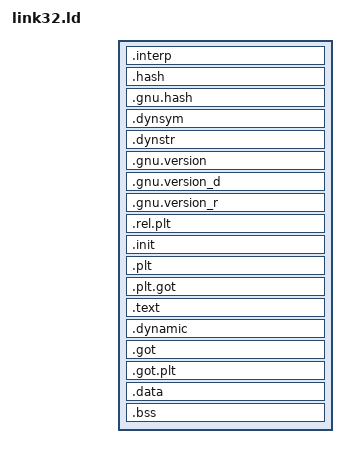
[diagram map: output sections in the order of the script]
/* Script for -z combreloc: combine and sort reloc sections */
/* Copyright (C) 2014-2015 Free Software Foundation, Inc.
   Copying and distribution of this script, with or without modification,
   are permitted in any medium without royalty provided the copyright
   notice and this notice are preserved.  */
OUTPUT_FORMAT("elf32-i386", "elf32-i386",
	      "elf32-i386")
OUTPUT_ARCH(i386)
ENTRY(_start)
SEARCH_DIR("=/usr/local/lib/i386-linux-gnu"); SEARCH_DIR("=/lib/i386-linux-gnu"); SEARCH_DIR("=/usr/lib/i386-linux-gnu"); SEARCH_DIR("=/usr/local/lib32"); SEARCH_DIR("=/lib32"); SEARCH_DIR("=/usr/lib32"); SEARCH_DIR("=/usr/local/lib"); SEARCH_DIR("=/lib"); SEARCH_DIR("=/usr/lib"); SEARCH_DIR("=/usr/i386-linux-gnu/lib32"); SEARCH_DIR("=/usr/x86_64-linux-gnu/lib32"); SEARCH_DIR("=/usr/i386-linux-gnu/lib");
SECTIONS
{
  /* Read-only sections, merged into text segment: */
  . = SEGMENT_START("text-segment", 0x08048000) + SIZEOF_HEADERS;
  .interp         : { *(.interp) }
  .hash           : { *(.hash) }
  .gnu.hash       : { *(.gnu.hash) }
  .dynsym         : { *(.dynsym) }
  .dynstr         : { *(.dynstr) }
  .gnu.version    : { *(.gnu.version) }
  .gnu.version_d  : { *(.gnu.version_d) }
  .gnu.version_r  : { *(.gnu.version_r) }
  .rel.plt        :
    {
      *(.rel.plt)
      PROVIDE_HIDDEN (__rel_iplt_start = .);
      *(.rel.iplt)
      PROVIDE_HIDDEN (__rel_iplt_end = .);
    }
  .init           :
  {
    KEEP (*(SORT_NONE(.init)))
  }
  .plt            : { *(.plt) *(.iplt) }
  .plt.got        : { *(.plt.got) }
  .text           :
  {
    *(.text .text.*)
    *(.rodata .rodata.*)
  }
  . = ALIGN(16);
  .dynamic        : { *(.dynamic) }
  .got            : { *(.got) *(.igot) }
  .got.plt        : { *(.got.plt)  *(.igot.plt) }
  .data           :
  {
    *(.data .data.* .gnu.linkonce.d.*)
    SORT(CONSTRUCTORS)
  }
  . = .;
  .bss            :
  {
   *(.dynbss)
   *(.bss .bss.* .gnu.linkonce.b.*)
   *(COMMON)
   . = ALIGN(. != 0 ? 32 / 8 : 1);
  }
  . = ALIGN(32 / 8);
  . = SEGMENT_START("ldata-segment", .);
  . = ALIGN(32 / 8);
}


